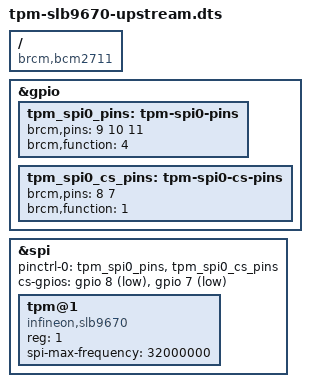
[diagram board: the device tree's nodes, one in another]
// Infineon SLB9670 TPM 2.0 on SPI0 CE1 (GPIO7) for the *upstream* bcm2711
// device tree used with Debian's arm64 kernel. The Pi OS tpm-slb9670 overlay
// can't apply here: it references Pi-DT-only labels (spi0, spidev1).
//
// Compiled on the node by roles/node_prep (boot_kernel.yml) with dtc -@.
/dts-v1/;
/plugin/;

/ {
	compatible = "brcm,bcm2711";

	// Pin groups: SCLK/MOSI/MISO on ALT0, both chip selects as GPIO outputs
	fragment@0 {
		target = <&gpio>;
		__overlay__ {
			tpm_spi0_pins: tpm-spi0-pins {
				brcm,pins = <9 10 11>;
				brcm,function = <4>; /* ALT0 */
			};
			tpm_spi0_cs_pins: tpm-spi0-cs-pins {
				brcm,pins = <8 7>;
				brcm,function = <1>; /* output */
			};
		};
	};

	fragment@1 {
		target = <&spi>;
		__overlay__ {
			#address-cells = <1>;
			#size-cells = <0>;
			pinctrl-names = "default";
			pinctrl-0 = <&tpm_spi0_pins &tpm_spi0_cs_pins>;
			cs-gpios = <&gpio 8 1>, <&gpio 7 1>; /* CE0, CE1; active low */
			status = "okay";

			tpm@1 {
				compatible = "infineon,slb9670", "tcg,tpm_tis-spi";
				reg = <1>;
				spi-max-frequency = <32000000>;
			};
		};
	};
};
